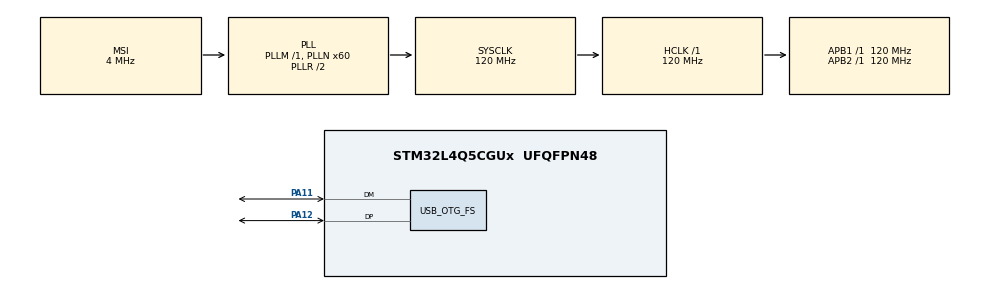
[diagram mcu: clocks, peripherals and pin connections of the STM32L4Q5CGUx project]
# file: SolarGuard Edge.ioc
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Mcu.Family=STM32L4
Mcu.Name=STM32L4Q5CGUx
Mcu.Package=UFQFPN48
NVIC.OTG_FS_IRQn=true\:0\:0\:false\:false\:true\:false\:true\:true
NVIC.PriorityGroup=NVIC_PRIORITYGROUP_4
PA11.Mode=Device_Only
PA11.Signal=USB_OTG_FS_DM
PA12.Mode=Device_Only
PA12.Signal=USB_OTG_FS_DP
PA13\ (JTMS/SWDIO).Mode=Serial_Wire
PA13\ (JTMS/SWDIO).Signal=SYS_JTMS-SWDIO
PA14\ (JTCK/SWCLK).Mode=Serial_Wire
PA14\ (JTCK/SWCLK).Signal=SYS_JTCK-SWCLK
PC14-OSC32_IN\ (PC14).Mode=LSE-External-Oscillator
PC14-OSC32_IN\ (PC14).Signal=RCC_OSC32_IN
PC15-OSC32_OUT\ (PC15).Mode=LSE-External-Oscillator
PC15-OSC32_OUT\ (PC15).Signal=RCC_OSC32_OUT
ProjectManager.HeapSize=0x200
ProjectManager.StackSize=0x400
ProjectManager.TargetToolchain=STM32CubeIDE
RCC.ADCFreq_Value=48000000
RCC.AHBFreq_Value=120000000
RCC.APB1Freq_Value=120000000
RCC.APB1TimFreq_Value=120000000
RCC.APB2Freq_Value=120000000
RCC.APB2TimFreq_Value=120000000
RCC.CortexFreq_Value=120000000
RCC.HCLKFreq_Value=120000000
RCC.HSE_VALUE=8000000
RCC.HSI48_VALUE=48000000
RCC.HSI_VALUE=16000000
RCC.MSI_VALUE=4000000
RCC.PLLN=60
RCC.PLLSAI1N=24
RCC.SYSCLKFreq_VALUE=120000000
RCC.SYSCLKSource=RCC_SYSCLKSOURCE_PLLCLK
RCC.USBFreq_Value=48000000
RCC.VCOOutputFreq_Value=240000000
USB_DEVICE.CLASS_NAME_FS=CDC
USB_DEVICE.VirtualMode=Cdc
USB_DEVICE.VirtualModeFS=Cdc_FS
USB_OTG_FS.VirtualMode=Device_Only
VP_USB_DEVICE_VS_USB_DEVICE_CDC_FS.Mode=CDC_FS
board=custom

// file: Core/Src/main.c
/* USER CODE BEGIN Header */
/**
  ******************************************************************************
  * @file           : main.c
  * @brief          : Main program body
  ******************************************************************************
  * @attention
  *
  * Copyright (c) 2026 STMicroelectronics.
  * All rights reserved.
  *
  * This software is licensed under terms that can be found in the LICENSE file
  * in the root directory of this software component.
  * If no LICENSE file comes with this software, it is provided AS-IS.
  *
  ******************************************************************************
  */
/* USER CODE END Header */
#include "main.h"
#include "usb_device.h"

/* USER CODE BEGIN Includes */
#include <stdio.h>
#include <string.h>
#include <stdarg.h>
#include "usbd_cdc_if.h"
#include <math.h>
/* USER CODE END Includes */

/* USER CODE BEGIN PTD */
#define FREQUENCY_HZ        10
#define INTERVAL_MS         (1000 / (FREQUENCY_HZ + 1))
static unsigned long last_interval_ms = 0;
/* USER CODE END PTD */

void SystemClock_Config(void);
static void MX_GPIO_Init(void);

/* USER CODE BEGIN 0 */

float voltage, current, power, temperature, ambientTemp, irradiance;

void vprint(const char *fmt, va_list argp)
    {
    char string[200];
    if (0 < vsprintf(string, fmt, argp)) // build string
	{
	CDC_Transmit_FS((uint8_t*) string, strlen(string));
	}
    }
void ei_printf(const char *format, ...)
    {
    va_list myargs;
    va_start(myargs, format);
    vprint(format, myargs);
    va_end(myargs);
    }
float sim_time = 0.0f;

float random_float(float min, float max)
{
    return min + ((float)rand() / (float)RAND_MAX) * (max - min);
}

/* USER CODE END 0 */

int main(void)
{

  /* MCU Configuration--------------------------------------------------------*/

  /* Reset of all peripherals, Initializes the Flash interface and the Systick. */
  HAL_Init();

  /* Configure the system clock */
  SystemClock_Config();

  /* Initialize all configured peripherals */
  MX_GPIO_Init();
  MX_USB_DEVICE_Init();
  /* USER CODE BEGIN 2 */
  temperature = 44.0f;
  /* USER CODE END 2 */

  /* Infinite loop */
  while (1)
  {

    /* USER CODE BEGIN 3 */

	  if (HAL_GetTick() > last_interval_ms + INTERVAL_MS)
	  	 	       	    {
	  	 	       	    last_interval_ms = HAL_GetTick();

	  	 	       	    ////// Normal

//	  	 	         sim_time += 0.1f;
//
//	  	 	      irradiance =
//	  	 	          750.0f
//	  	 	          + 230.0f * sinf(sim_time * 0.008f)
//	  	 	          + 20.0f  * sinf(sim_time * 0.035f);
//
//	  	 	      ambientTemp =
//	  	 	          27.0f
//	  	 	          + 2.0f * sinf(sim_time * 0.004f);
//
//	  	 	      current =
//	  	 	          8.5f * (irradiance / 850.0f)
//	  	 	          + 0.03f * sinf(sim_time * 0.7f);
//
//	  	 	      voltage =
//	  	 	          675.0f
//	  	 	          + 3.0f * sinf(sim_time * 0.02f)
//	  	 	          + 0.3f * sinf(sim_time * 0.8f);
//
//	  	 	      temperature =
//	  	 	          ambientTemp
//	  	 	          + 12.0f
//	  	 	          + 5.0f * (irradiance / 850.0f)
//	  	 	          + 0.1f * sinf(sim_time * 0.1f);
//
//	  	 	      power = voltage * current;
	  	 	       	    //////////////////////

	  	 	       	// CLOUD simulation

//	  	 	       	sim_time += 0.1f;
//
//
//	  	 	       	float baseIrradiance = 900.0f
//	  	 	       	        + 20.0f * sinf(sim_time * 0.025f);
//
//	  	 	       	// cloud
//	  	 	       	//  0 = not cloud
//	  	 	       	// ~1 = full closed cloud
//	  	 	       	float cloud = 0.5f + 0.5f * sinf(sim_time * 0.12f);
//
//
//	  	 	       	cloud = cloud * cloud;
//
//
//	  	 	       	irradiance =
//	  	 	       	        baseIrradiance * (1.0f - 0.68f * cloud)
//	  	 	       	        + 8.0f * sinf(sim_time * 0.9f);
//
//
//	  	 	       	if (irradiance < 200.0f)
//	  	 	       	    irradiance = 200.0f;
//
//	  	 	       	if (irradiance > 1000.0f)
//	  	 	       	    irradiance = 1000.0f;
//
//
//
//	  	 	       	current =
//	  	 	       	        8.5f * (irradiance / 850.0f)
//	  	 	       	        + 0.04f * sinf(sim_time * 0.7f);
//
//
//
//	  	 	       	voltage =
//	  	 	       	        675.0f
//	  	 	       	        + 3.0f * sinf(sim_time * 0.025f)
//	  	 	       	        - 4.0f * cloud
//	  	 	       	        + 0.3f * sinf(sim_time * 0.8f);
//
//
//
//	  	 	       	ambientTemp =
//	  	 	       	        27.0f
//	  	 	       	        + 1.0f * sinf(sim_time * 0.005f);
//
//
//
//	  	 	       	float targetTemp =
//	  	 	       	        ambientTemp
//	  	 	       	        + 12.0f
//	  	 	       	        + 5.0f * (irradiance / 850.0f);
//
//	  	 	       	temperature += (targetTemp - temperature) * 0.01f;
//
//
//
//	  	 	       	power = voltage * current;
	  	 	       	    /////////////////////////////////////

	  	 	       	// ================= OVERHEAT =================

	  	 	       	sim_time += 0.1f;

	  	 	       	irradiance =
	  	 	       	        850.0f
	  	 	       	        + 50.0f * sinf(sim_time * 0.02f)
	  	 	       	        + 10.0f * sinf(sim_time * 0.10f);

	  	 	       	ambientTemp =
	  	 	       	        27.0f
	  	 	       	        + 1.5f * sinf(sim_time * 0.005f);

	  	 	       	current =
	  	 	       	        8.5f * (irradiance / 850.0f)
	  	 	       	        + 0.03f * sinf(sim_time * 0.7f);

	  	 	       	voltage =
	  	 	       	        675.0f
	  	 	       	        + 2.0f * sinf(sim_time * 0.03f)
	  	 	       	        + 0.3f * sinf(sim_time * 0.8f);

	  	 	       	float normalTemp =
	  	 	       	        ambientTemp
	  	 	       	        + 12.0f
	  	 	       	        + 5.0f * (irradiance / 850.0f);

	  	 	       	float faultHeat =
	  	 	       	        20.0f +
	  	 	       	        20.0f * sinf(sim_time * 0.025f);

	  	 	       	float targetTemp = normalTemp + faultHeat;

	  	 	       	temperature +=
	  	 	       	        (targetTemp - temperature) * 0.015f;

	  	 	       	power = voltage * current;

	  	 	       	    /////////////////////////////

	  	 	       	// ================= BAD_CONTACT =================

//	  	 	       	sim_time += 0.1f;
//
//
//	  	 	       	irradiance =
//	  	 	       	        850.0f
//	  	 	       	        + 45.0f * sinf(sim_time * 0.018f)
//	  	 	       	        + 8.0f  * sinf(sim_time * 0.09f);
//
//
//	  	 	       	ambientTemp =
//	  	 	       	        27.0f
//	  	 	       	        + 1.5f * sinf(sim_time * 0.005f);
//
//
//
//	  	 	       	float normalCurrent =
//	  	 	       	        8.5f * (irradiance / 850.0f);
//
//
//
//	  	 	       	float degradation =
//	  	 	       	        0.5f + 0.5f * sinf(sim_time * 0.018f);
//
//
//
//	  	 	       	current =
//	  	 	       	        normalCurrent * (1.0f - 0.10f * degradation)
//	  	 	       	        + 0.03f * sinf(sim_time * 0.65f);
//
//
//
//	  	 	       	voltage =
//	  	 	       	        675.0f
//	  	 	       	        - 8.0f * degradation
//	  	 	       	        + 2.0f * sinf(sim_time * 0.025f);
//
//
//
//
//	  	 	     float normalTemp =
//	  	 	             ambientTemp
//	  	 	             + 12.0f
//	  	 	             + 5.0f * (irradiance / 850.0f);
//
//
//
//	  	 	     float faultHeat =
//	  	 	             6.0f
//	  	 	             + 6.0f * degradation;
//
//	  	 	     float targetTemp = normalTemp + faultHeat;
//
//
//
//	  	 	     if (targetTemp > 58.0f)
//	  	 	     {
//	  	 	         targetTemp = 58.0f;
//	  	 	     }
//
//
//
//	  	 	     temperature +=
//	  	 	             (targetTemp - temperature) * 0.012f;
//
//
//
//	  	 	     if (temperature > 58.0f)
//	  	 	     {
//	  	 	         temperature = 58.0f;
//	  	 	     }
//
//
//
//	  	 	       	power = voltage * current;
	  	 	       	    //////////////////////////////

	  ei_printf("%.2f,%.2f,%.2f,%.2f,%.2f,%.2f\n",voltage, current, power, temperature, ambientTemp, irradiance);
	  	 	       	    }
  }
  /* USER CODE END 3 */
}

void SystemClock_Config(void)
{
  RCC_OscInitTypeDef RCC_OscInitStruct = {0};
  RCC_ClkInitTypeDef RCC_ClkInitStruct = {0};

  /** Configure the main internal regulator output voltage
  */
  if (HAL_PWREx_ControlVoltageScaling(PWR_REGULATOR_VOLTAGE_SCALE1_BOOST) != HAL_OK)
  {
    Error_Handler();
  }

  /** Configure LSE Drive Capability
  */
  HAL_PWR_EnableBkUpAccess();
  __HAL_RCC_LSEDRIVE_CONFIG(RCC_LSEDRIVE_LOW);

  /** Initializes the RCC Oscillators according to the specified parameters
  * in the RCC_OscInitTypeDef structure.
  */
  RCC_OscInitStruct.OscillatorType = RCC_OSCILLATORTYPE_LSE|RCC_OSCILLATORTYPE_MSI;
  RCC_OscInitStruct.LSEState = RCC_LSE_ON;
  RCC_OscInitStruct.MSIState = RCC_MSI_ON;
  RCC_OscInitStruct.MSICalibrationValue = 0;
  RCC_OscInitStruct.MSIClockRange = RCC_MSIRANGE_6;
  RCC_OscInitStruct.PLL.PLLState = RCC_PLL_ON;
  RCC_OscInitStruct.PLL.PLLSource = RCC_PLLSOURCE_MSI;
  RCC_OscInitStruct.PLL.PLLM = 1;
  RCC_OscInitStruct.PLL.PLLN = 60;
  RCC_OscInitStruct.PLL.PLLP = RCC_PLLP_DIV2;
  RCC_OscInitStruct.PLL.PLLQ = RCC_PLLQ_DIV2;
  RCC_OscInitStruct.PLL.PLLR = RCC_PLLR_DIV2;
  if (HAL_RCC_OscConfig(&RCC_OscInitStruct) != HAL_OK)
  {
    Error_Handler();
  }

  /** Initializes the CPU, AHB and APB buses clocks
  */
  RCC_ClkInitStruct.ClockType = RCC_CLOCKTYPE_HCLK|RCC_CLOCKTYPE_SYSCLK
                              |RCC_CLOCKTYPE_PCLK1|RCC_CLOCKTYPE_PCLK2;
  RCC_ClkInitStruct.SYSCLKSource = RCC_SYSCLKSOURCE_PLLCLK;
  RCC_ClkInitStruct.AHBCLKDivider = RCC_SYSCLK_DIV1;
  RCC_ClkInitStruct.APB1CLKDivider = RCC_HCLK_DIV1;
  RCC_ClkInitStruct.APB2CLKDivider = RCC_HCLK_DIV1;

  if (HAL_RCC_ClockConfig(&RCC_ClkInitStruct, FLASH_LATENCY_5) != HAL_OK)
  {
    Error_Handler();
  }

  /** Enable MSI Auto calibration
  */
  HAL_RCCEx_EnableMSIPLLMode();
}

static void MX_GPIO_Init(void)
{

  /* GPIO Ports Clock Enable */
  __HAL_RCC_GPIOC_CLK_ENABLE();
  __HAL_RCC_GPIOA_CLK_ENABLE();

}

void Error_Handler(void)
{
  __disable_irq();
  while (1)
  {
  }
}
